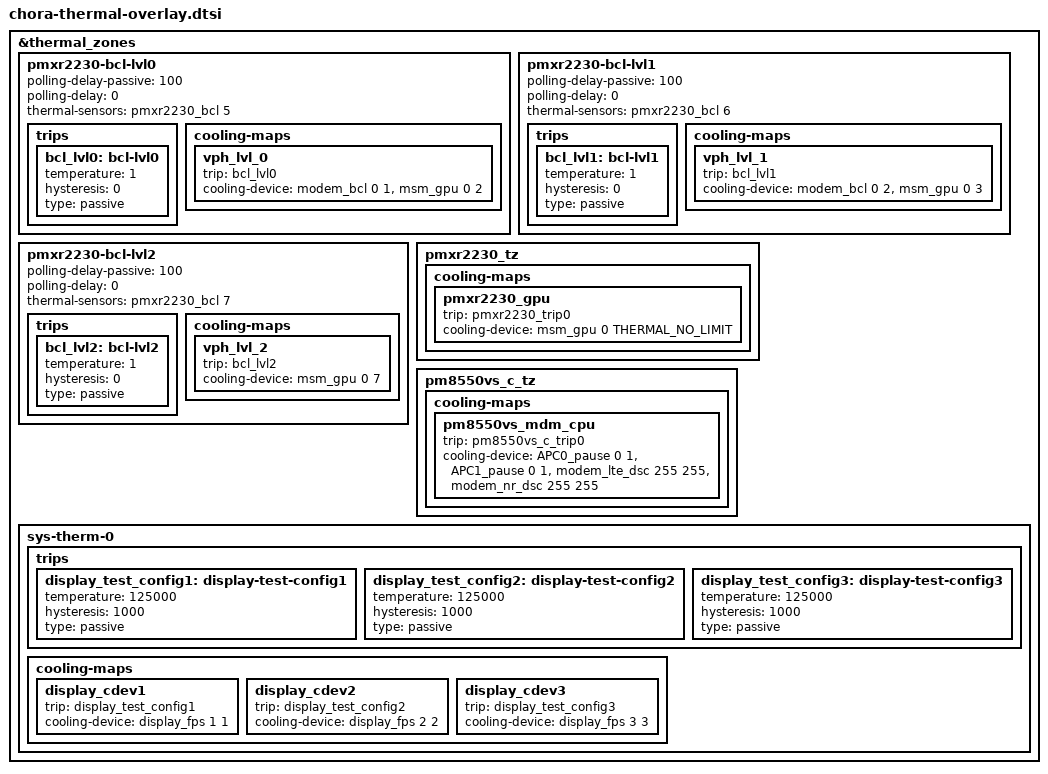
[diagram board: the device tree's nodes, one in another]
// SPDX-License-Identifier: BSD-3-Clause
/*
 * Copyright (c) Qualcomm Technologies, Inc. and/or its subsidiaries.
 */

#include <dt-bindings/thermal/thermal_qti.h>

&thermal_zones {
	pmxr2230-bcl-lvl0 {
		polling-delay-passive = <100>;
		polling-delay = <0>;
		thermal-sensors = <&pmxr2230_bcl 5>;

		trips {
			bcl_lvl0: bcl-lvl0 {
				temperature = <1>;
				hysteresis = <0>;
				type = "passive";
			};
		};

		cooling-maps {
			vph_lvl_0 {
				trip = <&bcl_lvl0>;
				cooling-device = <&modem_bcl 0 1>,
					<&msm_gpu 0 2>;
			};
		};
	};

	pmxr2230-bcl-lvl1 {
		polling-delay-passive = <100>;
		polling-delay = <0>;
		thermal-sensors = <&pmxr2230_bcl 6>;

		trips {
			bcl_lvl1: bcl-lvl1 {
				temperature = <1>;
				hysteresis = <0>;
				type = "passive";
			};
		};

		cooling-maps {
			vph_lvl_1 {
				trip = <&bcl_lvl1>;
				cooling-device = <&modem_bcl 0 2>,
					<&msm_gpu 0 3>;
			};
		};
	};

	pmxr2230-bcl-lvl2 {
		polling-delay-passive = <100>;
		polling-delay = <0>;
		thermal-sensors = <&pmxr2230_bcl 7>;

		trips {
			bcl_lvl2: bcl-lvl2 {
				temperature = <1>;
				hysteresis = <0>;
				type = "passive";
			};
		};

		cooling-maps {
			vph_lvl_2 {
				trip = <&bcl_lvl2>;
				cooling-device = <&msm_gpu 0 7>;
			};
		};
	};

	pmxr2230_tz {
		cooling-maps {
			pmxr2230_gpu {
				trip = <&pmxr2230_trip0>;
				cooling-device = <&msm_gpu 0 THERMAL_NO_LIMIT>;
			};
		};
	};

	pm8550vs_c_tz {
		cooling-maps {
			pm8550vs_mdm_cpu {
				trip = <&pm8550vs_c_trip0>;
				cooling-device = <&APC0_pause 0 1>,
					<&APC1_pause 0 1>,
					<&modem_lte_dsc 255 255>,
					<&modem_nr_dsc 255 255>;
			};
		};
	};

	sys-therm-0 {
		trips {
			display_test_config1: display-test-config1 {
				temperature = <125000>;
				hysteresis = <1000>;
				type = "passive";
			};

			display_test_config2: display-test-config2 {
				temperature = <125000>;
				hysteresis = <1000>;
				type = "passive";
			};

			display_test_config3: display-test-config3 {
				temperature = <125000>;
				hysteresis = <1000>;
				type = "passive";
			};
		};

		cooling-maps {
			display_cdev1 {
				trip = <&display_test_config1>;
				cooling-device = <&display_fps 1 1>;
			};

			display_cdev2 {
				trip = <&display_test_config2>;
				cooling-device = <&display_fps 2 2>;
			};

			display_cdev3 {
				trip = <&display_test_config3>;
				cooling-device = <&display_fps 3 3>;
			};
		};
	};
};
